VERSION ""

NS_ :

BS_:

BU_: BCM CTIS DCU EBS ENG GW HUMS INS PMC SAS1 SAS2 TCU VCU

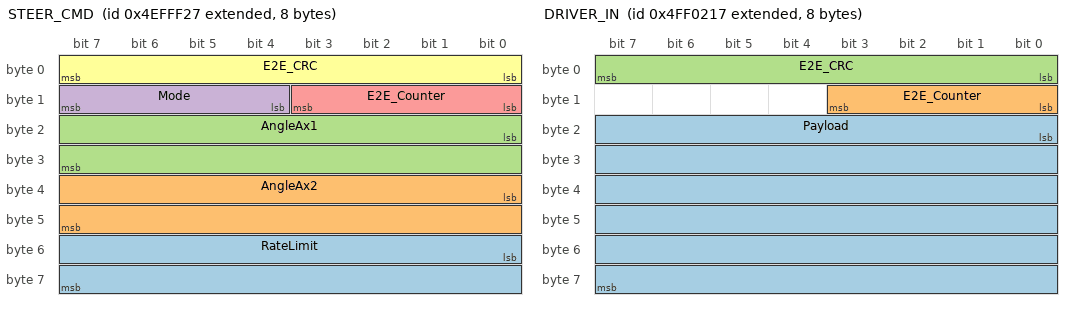
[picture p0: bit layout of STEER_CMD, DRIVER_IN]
BO_ 2230320935 STEER_CMD: 8 VCU
 SG_ RateLimit : 48|16@1+ (0.1,0) [0|0] "deg/s"  BCM,CTIS,DCU,EBS,ENG,GW,HUMS,INS,PMC,SAS1,SAS2,TCU
 SG_ AngleAx2 : 32|16@1- (0.01,0) [0|0] "deg"  BCM,CTIS,DCU,EBS,ENG,GW,HUMS,INS,PMC,SAS1,SAS2,TCU
 SG_ AngleAx1 : 16|16@1- (0.01,0) [0|0] "deg"  BCM,CTIS,DCU,EBS,ENG,GW,HUMS,INS,PMC,SAS1,SAS2,TCU
 SG_ Mode : 12|4@1+ (1,0) [0|0] ""  BCM,CTIS,DCU,EBS,ENG,GW,HUMS,INS,PMC,SAS1,SAS2,TCU
 SG_ E2E_Counter : 8|4@1+ (1,0) [0|0] ""  BCM,CTIS,DCU,EBS,ENG,GW,HUMS,INS,PMC,SAS1,SAS2,TCU
 SG_ E2E_CRC : 0|8@1+ (1,0) [0|0] ""  BCM,CTIS,DCU,EBS,ENG,GW,HUMS,INS,PMC,SAS1,SAS2,TCU

BO_ 2231304727 DRIVER_IN: 8 DCU
 SG_ Payload : 16|48@1+ (1,0) [0|0] ""  BCM,CTIS,EBS,ENG,GW,HUMS,INS,PMC,SAS1,SAS2,TCU,VCU
 SG_ E2E_Counter : 8|4@1+ (1,0) [0|0] ""  BCM,CTIS,EBS,ENG,GW,HUMS,INS,PMC,SAS1,SAS2,TCU,VCU
 SG_ E2E_CRC : 0|8@1+ (1,0) [0|0] ""  BCM,CTIS,EBS,ENG,GW,HUMS,INS,PMC,SAS1,SAS2,TCU,VCU

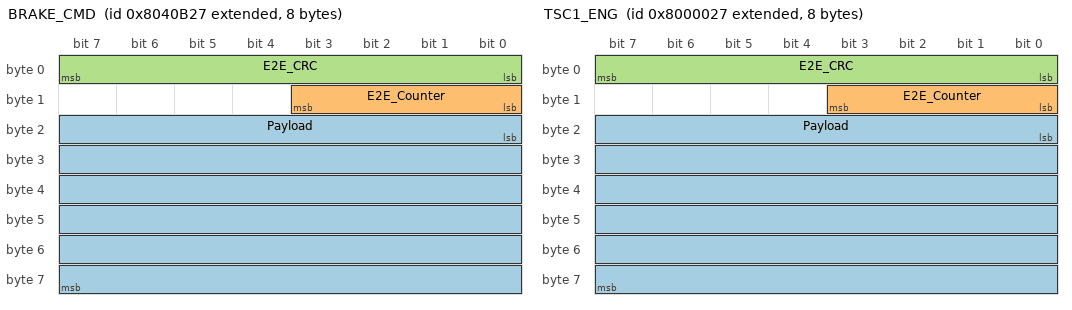
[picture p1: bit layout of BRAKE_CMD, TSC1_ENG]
BO_ 2281966375 BRAKE_CMD: 8 VCU
 SG_ Payload : 16|48@1+ (1,0) [0|0] ""  BCM,CTIS,DCU,EBS,ENG,GW,HUMS,INS,PMC,SAS1,SAS2,TCU
 SG_ E2E_Counter : 8|4@1+ (1,0) [0|0] ""  BCM,CTIS,DCU,EBS,ENG,GW,HUMS,INS,PMC,SAS1,SAS2,TCU
 SG_ E2E_CRC : 0|8@1+ (1,0) [0|0] ""  BCM,CTIS,DCU,EBS,ENG,GW,HUMS,INS,PMC,SAS1,SAS2,TCU

BO_ 2281701415 TSC1_ENG: 8 VCU
 SG_ Payload : 16|48@1+ (1,0) [0|0] ""  BCM,CTIS,DCU,EBS,ENG,GW,HUMS,INS,PMC,SAS1,SAS2,TCU
 SG_ E2E_Counter : 8|4@1+ (1,0) [0|0] ""  BCM,CTIS,DCU,EBS,ENG,GW,HUMS,INS,PMC,SAS1,SAS2,TCU
 SG_ E2E_CRC : 0|8@1+ (1,0) [0|0] ""  BCM,CTIS,DCU,EBS,ENG,GW,HUMS,INS,PMC,SAS1,SAS2,TCU

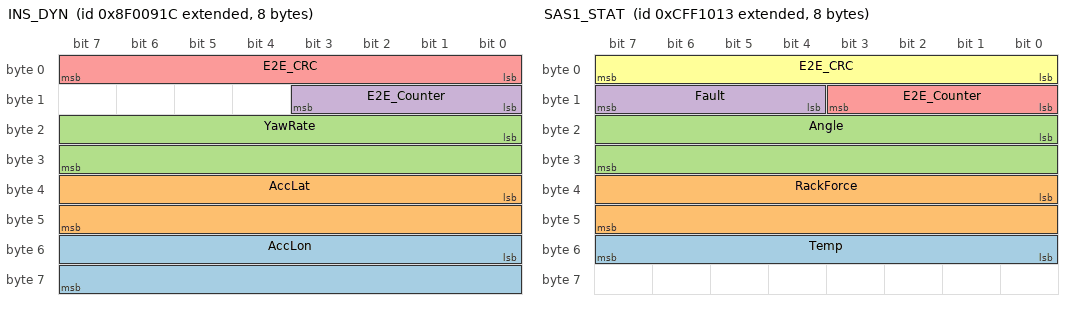
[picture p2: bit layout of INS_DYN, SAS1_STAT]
BO_ 2297432348 INS_DYN: 8 INS
 SG_ AccLon : 48|16@1- (0.001,0) [0|0] "m/s2"  BCM,CTIS,DCU,EBS,ENG,GW,HUMS,PMC,SAS1,SAS2,TCU,VCU
 SG_ AccLat : 32|16@1- (0.001,0) [0|0] "m/s2"  BCM,CTIS,DCU,EBS,ENG,GW,HUMS,PMC,SAS1,SAS2,TCU,VCU
 SG_ YawRate : 16|16@1- (0.002,0) [0|0] "rad/s"  BCM,CTIS,DCU,EBS,ENG,GW,HUMS,PMC,SAS1,SAS2,TCU,VCU
 SG_ E2E_Counter : 8|4@1+ (1,0) [0|0] ""  BCM,CTIS,DCU,EBS,ENG,GW,HUMS,PMC,SAS1,SAS2,TCU,VCU
 SG_ E2E_CRC : 0|8@1+ (1,0) [0|0] ""  BCM,CTIS,DCU,EBS,ENG,GW,HUMS,PMC,SAS1,SAS2,TCU,VCU

BO_ 2365526035 SAS1_STAT: 8 SAS1
 SG_ Temp : 48|8@1+ (1,-40) [0|0] "degC"  BCM,CTIS,DCU,EBS,ENG,GW,HUMS,INS,PMC,SAS2,TCU,VCU
 SG_ RackForce : 32|16@1- (1,0) [0|0] "N"  BCM,CTIS,DCU,EBS,ENG,GW,HUMS,INS,PMC,SAS2,TCU,VCU
 SG_ Angle : 16|16@1- (0.01,0) [0|0] "deg"  BCM,CTIS,DCU,EBS,ENG,GW,HUMS,INS,PMC,SAS2,TCU,VCU
 SG_ Fault : 12|4@1+ (1,0) [0|0] ""  BCM,CTIS,DCU,EBS,ENG,GW,HUMS,INS,PMC,SAS2,TCU,VCU
 SG_ E2E_Counter : 8|4@1+ (1,0) [0|0] ""  BCM,CTIS,DCU,EBS,ENG,GW,HUMS,INS,PMC,SAS2,TCU,VCU
 SG_ E2E_CRC : 0|8@1+ (1,0) [0|0] ""  BCM,CTIS,DCU,EBS,ENG,GW,HUMS,INS,PMC,SAS2,TCU,VCU

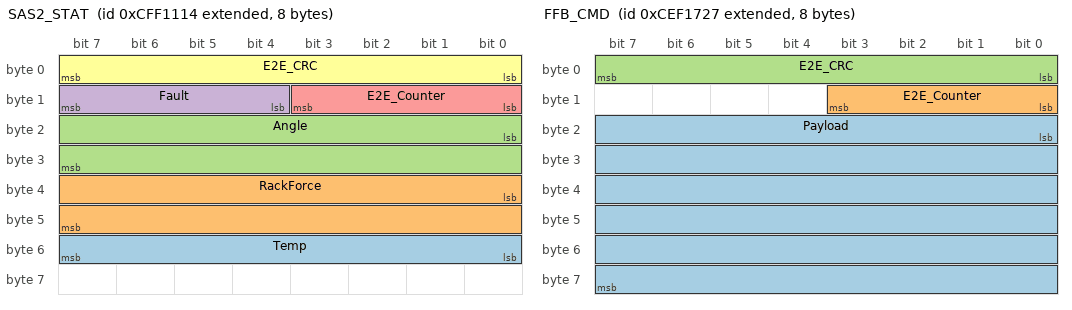
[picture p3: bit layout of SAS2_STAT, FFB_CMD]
BO_ 2365526292 SAS2_STAT: 8 SAS2
 SG_ Temp : 48|8@1+ (1,-40) [0|0] "degC"  BCM,CTIS,DCU,EBS,ENG,GW,HUMS,INS,PMC,SAS1,TCU,VCU
 SG_ RackForce : 32|16@1- (1,0) [0|0] "N"  BCM,CTIS,DCU,EBS,ENG,GW,HUMS,INS,PMC,SAS1,TCU,VCU
 SG_ Angle : 16|16@1- (0.01,0) [0|0] "deg"  BCM,CTIS,DCU,EBS,ENG,GW,HUMS,INS,PMC,SAS1,TCU,VCU
 SG_ Fault : 12|4@1+ (1,0) [0|0] ""  BCM,CTIS,DCU,EBS,ENG,GW,HUMS,INS,PMC,SAS1,TCU,VCU
 SG_ E2E_Counter : 8|4@1+ (1,0) [0|0] ""  BCM,CTIS,DCU,EBS,ENG,GW,HUMS,INS,PMC,SAS1,TCU,VCU
 SG_ E2E_CRC : 0|8@1+ (1,0) [0|0] ""  BCM,CTIS,DCU,EBS,ENG,GW,HUMS,INS,PMC,SAS1,TCU,VCU

BO_ 2365530123 WSPD_1: 8 EBS
 SG_ Payload : 0|64@1+ (1,0) [0|0] ""  BCM,CTIS,DCU,ENG,GW,HUMS,INS,PMC,SAS1,SAS2,TCU,VCU

BO_ 2365530379 WSPD_2: 8 EBS
 SG_ Payload : 0|64@1+ (1,0) [0|0] ""  BCM,CTIS,DCU,ENG,GW,HUMS,INS,PMC,SAS1,SAS2,TCU,VCU

BO_ 2364479271 FFB_CMD: 8 VCU
 SG_ Payload : 16|48@1+ (1,0) [0|0] ""  BCM,CTIS,DCU,EBS,ENG,GW,HUMS,INS,PMC,SAS1,SAS2,TCU
 SG_ E2E_Counter : 8|4@1+ (1,0) [0|0] ""  BCM,CTIS,DCU,EBS,ENG,GW,HUMS,INS,PMC,SAS1,SAS2,TCU
 SG_ E2E_CRC : 0|8@1+ (1,0) [0|0] ""  BCM,CTIS,DCU,EBS,ENG,GW,HUMS,INS,PMC,SAS1,SAS2,TCU

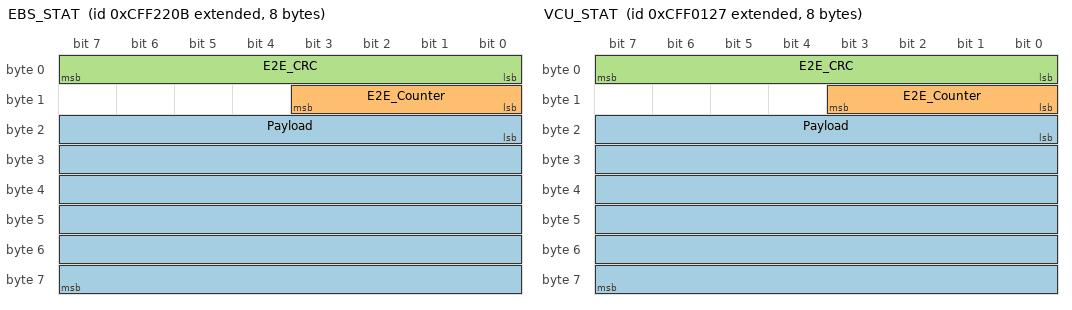
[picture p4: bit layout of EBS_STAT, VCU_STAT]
BO_ 2365530635 EBS_STAT: 8 EBS
 SG_ Payload : 16|48@1+ (1,0) [0|0] ""  BCM,CTIS,DCU,ENG,GW,HUMS,INS,PMC,SAS1,SAS2,TCU,VCU
 SG_ E2E_Counter : 8|4@1+ (1,0) [0|0] ""  BCM,CTIS,DCU,ENG,GW,HUMS,INS,PMC,SAS1,SAS2,TCU,VCU
 SG_ E2E_CRC : 0|8@1+ (1,0) [0|0] ""  BCM,CTIS,DCU,ENG,GW,HUMS,INS,PMC,SAS1,SAS2,TCU,VCU

BO_ 2365522215 VCU_STAT: 8 VCU
 SG_ Payload : 16|48@1+ (1,0) [0|0] ""  BCM,CTIS,DCU,EBS,ENG,GW,HUMS,INS,PMC,SAS1,SAS2,TCU
 SG_ E2E_Counter : 8|4@1+ (1,0) [0|0] ""  BCM,CTIS,DCU,EBS,ENG,GW,HUMS,INS,PMC,SAS1,SAS2,TCU
 SG_ E2E_CRC : 0|8@1+ (1,0) [0|0] ""  BCM,CTIS,DCU,EBS,ENG,GW,HUMS,INS,PMC,SAS1,SAS2,TCU

BO_ 2565865739 EBC1: 8 EBS
 SG_ Payload : 0|64@1+ (1,0) [0|0] ""  BCM,CTIS,DCU,ENG,GW,HUMS,INS,PMC,SAS1,SAS2,TCU,VCU

BO_ 2364539395 ETC1: 8 TCU
 SG_ Payload : 0|64@1+ (1,0) [0|0] ""  BCM,CTIS,DCU,EBS,ENG,GW,HUMS,INS,PMC,SAS1,SAS2,VCU

BO_ 2364539904 EEC1: 8 ENG
 SG_ Payload : 0|64@1+ (1,0) [0|0] ""  BCM,CTIS,DCU,EBS,GW,HUMS,INS,PMC,SAS1,SAS2,TCU,VCU

BO_ 2364539648 EEC2: 8 ENG
 SG_ Payload : 0|64@1+ (1,0) [0|0] ""  BCM,CTIS,DCU,EBS,GW,HUMS,INS,PMC,SAS1,SAS2,TCU,VCU

BO_ 2565866755 ETC2: 8 TCU
 SG_ Payload : 0|64@1+ (1,0) [0|0] ""  BCM,CTIS,DCU,EBS,ENG,GW,HUMS,INS,PMC,SAS1,SAS2,VCU

BO_ 2566844711 CCVS: 8 VCU
 SG_ Payload : 0|64@1+ (1,0) [0|0] ""  BCM,CTIS,DCU,EBS,ENG,GW,HUMS,INS,PMC,SAS1,SAS2,TCU

BO_ 2566844928 LFE: 8 ENG
 SG_ Payload : 0|64@1+ (1,0) [0|0] ""  BCM,CTIS,DCU,EBS,GW,HUMS,INS,PMC,SAS1,SAS2,TCU,VCU

BO_ 2566843904 ET1: 8 ENG
 SG_ Payload : 0|64@1+ (1,0) [0|0] ""  BCM,CTIS,DCU,EBS,GW,HUMS,INS,PMC,SAS1,SAS2,TCU,VCU

BO_ 2566845696 AMB: 8 ENG
 SG_ Payload : 0|64@1+ (1,0) [0|0] ""  BCM,CTIS,DCU,EBS,GW,HUMS,INS,PMC,SAS1,SAS2,TCU,VCU

BO_ 2566841600 HOURS: 8 ENG
 SG_ Payload : 0|64@1+ (1,0) [0|0] ""  BCM,CTIS,DCU,EBS,GW,HUMS,INS,PMC,SAS1,SAS2,TCU,VCU

BO_ 2566842624 LFC: 8 ENG
 SG_ Payload : 0|64@1+ (1,0) [0|0] ""  BCM,CTIS,DCU,EBS,GW,HUMS,INS,PMC,SAS1,SAS2,TCU,VCU

BO_ 2566847521 DD: 8 BCM
 SG_ Payload : 0|64@1+ (1,0) [0|0] ""  CTIS,DCU,EBS,ENG,GW,HUMS,INS,PMC,SAS1,SAS2,TCU,VCU

BO_ 2566832423 VDHR: 8 VCU
 SG_ Payload : 0|64@1+ (1,0) [0|0] ""  BCM,CTIS,DCU,EBS,ENG,GW,HUMS,INS,PMC,SAS1,SAS2,TCU

BO_ 2499751975 CTIS_CMD: 8 VCU
 SG_ Payload : 0|64@1+ (1,0) [0|0] ""  BCM,CTIS,DCU,EBS,ENG,GW,HUMS,INS,PMC,SAS1,SAS2,TCU

BO_ 2499752243 CTIS_STAT: 8 CTIS
 SG_ Payload : 0|64@1+ (1,0) [0|0] ""  BCM,DCU,EBS,ENG,GW,HUMS,INS,PMC,SAS1,SAS2,TCU,VCU

BO_ 2566845491 TIRE: 8 CTIS
 SG_ Payload : 0|64@1+ (1,0) [0|0] ""  BCM,DCU,EBS,ENG,GW,HUMS,INS,PMC,SAS1,SAS2,TCU,VCU

BO_ 2499756101 PMC_STAT: 8 PMC
 SG_ Payload : 0|64@1+ (1,0) [0|0] ""  BCM,CTIS,DCU,EBS,ENG,GW,HUMS,INS,SAS1,SAS2,TCU,VCU

BO_ 2499756357 PMC_SSPC: 8 PMC
 SG_ Payload : 0|64@1+ (1,0) [0|0] ""  BCM,CTIS,DCU,EBS,ENG,GW,HUMS,INS,SAS1,SAS2,TCU,VCU

BO_ 2499756583 PMC_CMD: 8 VCU
 SG_ Payload : 0|64@1+ (1,0) [0|0] ""  BCM,CTIS,DCU,EBS,ENG,GW,HUMS,INS,PMC,SAS1,SAS2,TCU

BO_ 2566869025 BCM_LIGHT: 8 BCM
 SG_ Payload : 0|64@1+ (1,0) [0|0] ""  CTIS,DCU,EBS,ENG,GW,HUMS,INS,PMC,SAS1,SAS2,TCU,VCU

BO_ 2566869281 BCM_HATCH: 8 BCM
 SG_ Payload : 0|64@1+ (1,0) [0|0] ""  CTIS,DCU,EBS,ENG,GW,HUMS,INS,PMC,SAS1,SAS2,TCU,VCU

BO_ 2432651809 CBRN_STAT: 8 BCM
 SG_ Payload : 0|64@1+ (1,0) [0|0] ""  CTIS,DCU,EBS,ENG,GW,HUMS,INS,PMC,SAS1,SAS2,TCU,VCU

BO_ 2566865733 PMC_BATT: 8 PMC
 SG_ Payload : 0|64@1+ (1,0) [0|0] ""  BCM,CTIS,DCU,EBS,ENG,GW,HUMS,INS,SAS1,SAS2,TCU,VCU

BO_ 2566834688 DM1_ENG: 8 ENG
 SG_ Payload : 0|64@1+ (1,0) [0|0] ""  BCM,CTIS,DCU,EBS,GW,HUMS,INS,PMC,SAS1,SAS2,TCU,VCU

BO_ 2566834691 DM1_TCU: 8 TCU
 SG_ Payload : 0|64@1+ (1,0) [0|0] ""  BCM,CTIS,DCU,EBS,ENG,GW,HUMS,INS,PMC,SAS1,SAS2,VCU

BO_ 2566834699 DM1_EBS: 8 EBS
 SG_ Payload : 0|64@1+ (1,0) [0|0] ""  BCM,CTIS,DCU,ENG,GW,HUMS,INS,PMC,SAS1,SAS2,TCU,VCU

BO_ 2566834727 DM1_VCU: 8 VCU
 SG_ Payload : 0|64@1+ (1,0) [0|0] ""  BCM,CTIS,DCU,EBS,ENG,GW,HUMS,INS,PMC,SAS1,SAS2,TCU

BO_ 2566834707 DM1_SAS1: 8 SAS1
 SG_ Payload : 0|64@1+ (1,0) [0|0] ""  BCM,CTIS,DCU,EBS,ENG,GW,HUMS,INS,PMC,SAS2,TCU,VCU

BO_ 2566834708 DM1_SAS2: 8 SAS2
 SG_ Payload : 0|64@1+ (1,0) [0|0] ""  BCM,CTIS,DCU,EBS,ENG,GW,HUMS,INS,PMC,SAS1,TCU,VCU

BO_ 2566834739 DM1_CTIS: 8 CTIS
 SG_ Payload : 0|64@1+ (1,0) [0|0] ""  BCM,DCU,EBS,ENG,GW,HUMS,INS,PMC,SAS1,SAS2,TCU,VCU

BO_ 2566834757 DM1_PMC: 8 PMC
 SG_ Payload : 0|64@1+ (1,0) [0|0] ""  BCM,CTIS,DCU,EBS,ENG,GW,HUMS,INS,SAS1,SAS2,TCU,VCU

BO_ 2632711936 TP_DT_ENG: 8 ENG
 SG_ Payload : 0|64@1+ (1,0) [0|0] ""  BCM,CTIS,DCU,EBS,GW,HUMS,INS,PMC,SAS1,SAS2,TCU,VCU

BO_ 2632711947 TP_DT_EBS: 8 EBS
 SG_ Payload : 0|64@1+ (1,0) [0|0] ""  BCM,CTIS,DCU,ENG,GW,HUMS,INS,PMC,SAS1,SAS2,TCU,VCU

BO_ 2565537610 HUMS_REQ: 3 HUMS
 SG_ Payload : 0|24@1+ (1,0) [0|0] ""  BCM,CTIS,DCU,EBS,ENG,GW,INS,PMC,SAS1,SAS2,TCU,VCU

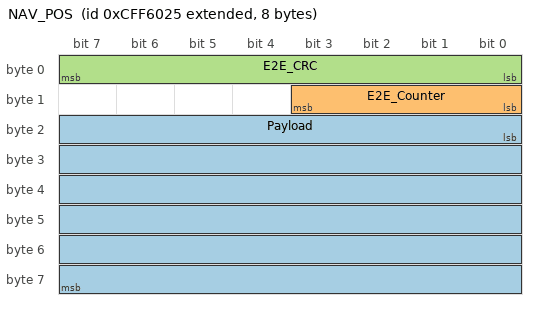
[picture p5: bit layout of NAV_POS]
BO_ 2365546533 NAV_POS: 8 GW
 SG_ Payload : 16|48@1+ (1,0) [0|0] ""  BCM,CTIS,DCU,EBS,ENG,HUMS,INS,PMC,SAS1,SAS2,TCU,VCU
 SG_ E2E_Counter : 8|4@1+ (1,0) [0|0] ""  BCM,CTIS,DCU,EBS,ENG,HUMS,INS,PMC,SAS1,SAS2,TCU,VCU
 SG_ E2E_CRC : 0|8@1+ (1,0) [0|0] ""  BCM,CTIS,DCU,EBS,ENG,HUMS,INS,PMC,SAS1,SAS2,TCU,VCU

BO_ 2499764517 C2_MODE: 8 GW
 SG_ Payload : 0|64@1+ (1,0) [0|0] ""  BCM,CTIS,DCU,EBS,ENG,HUMS,INS,PMC,SAS1,SAS2,TCU,VCU

BA_DEF_ BO_  "GenMsgCycleTime" INT 0 65535;
BA_DEF_DEF_  "GenMsgCycleTime" 0;
BA_ "GenMsgCycleTime" BO_ 2230320935 10;
BA_ "GenMsgCycleTime" BO_ 2231304727 10;
BA_ "GenMsgCycleTime" BO_ 2281966375 10;
BA_ "GenMsgCycleTime" BO_ 2281701415 10;
BA_ "GenMsgCycleTime" BO_ 2297432348 10;
BA_ "GenMsgCycleTime" BO_ 2365526035 10;
BA_ "GenMsgCycleTime" BO_ 2365526292 10;
BA_ "GenMsgCycleTime" BO_ 2365530123 10;
BA_ "GenMsgCycleTime" BO_ 2365530379 10;
BA_ "GenMsgCycleTime" BO_ 2364479271 10;
BA_ "GenMsgCycleTime" BO_ 2365530635 20;
BA_ "GenMsgCycleTime" BO_ 2365522215 20;
BA_ "GenMsgCycleTime" BO_ 2565865739 100;
BA_ "GenMsgCycleTime" BO_ 2364539395 10;
BA_ "GenMsgCycleTime" BO_ 2364539904 20;
BA_ "GenMsgCycleTime" BO_ 2364539648 50;
BA_ "GenMsgCycleTime" BO_ 2565866755 100;
BA_ "GenMsgCycleTime" BO_ 2566844711 100;
BA_ "GenMsgCycleTime" BO_ 2566844928 100;
BA_ "GenMsgCycleTime" BO_ 2566843904 1000;
BA_ "GenMsgCycleTime" BO_ 2566845696 1000;
BA_ "GenMsgCycleTime" BO_ 2566841600 1000;
BA_ "GenMsgCycleTime" BO_ 2566842624 1000;
BA_ "GenMsgCycleTime" BO_ 2566847521 1000;
BA_ "GenMsgCycleTime" BO_ 2566832423 1000;
BA_ "GenMsgCycleTime" BO_ 2499751975 100;
BA_ "GenMsgCycleTime" BO_ 2499752243 100;
BA_ "GenMsgCycleTime" BO_ 2566845491 1000;
BA_ "GenMsgCycleTime" BO_ 2499756101 100;
BA_ "GenMsgCycleTime" BO_ 2499756357 100;
BA_ "GenMsgCycleTime" BO_ 2499756583 100;
BA_ "GenMsgCycleTime" BO_ 2566869025 100;
BA_ "GenMsgCycleTime" BO_ 2566869281 500;
BA_ "GenMsgCycleTime" BO_ 2432651809 500;
BA_ "GenMsgCycleTime" BO_ 2566865733 1000;
BA_ "GenMsgCycleTime" BO_ 2566834688 1000;
BA_ "GenMsgCycleTime" BO_ 2566834691 1000;
BA_ "GenMsgCycleTime" BO_ 2566834699 1000;
BA_ "GenMsgCycleTime" BO_ 2566834727 1000;
BA_ "GenMsgCycleTime" BO_ 2566834707 1000;
BA_ "GenMsgCycleTime" BO_ 2566834708 1000;
BA_ "GenMsgCycleTime" BO_ 2566834739 1000;
BA_ "GenMsgCycleTime" BO_ 2566834757 1000;
BA_ "GenMsgCycleTime" BO_ 2632711936 50;
BA_ "GenMsgCycleTime" BO_ 2632711947 50;
BA_ "GenMsgCycleTime" BO_ 2565537610 100;
BA_ "GenMsgCycleTime" BO_ 2365546533 10;
BA_ "GenMsgCycleTime" BO_ 2499764517 100;
